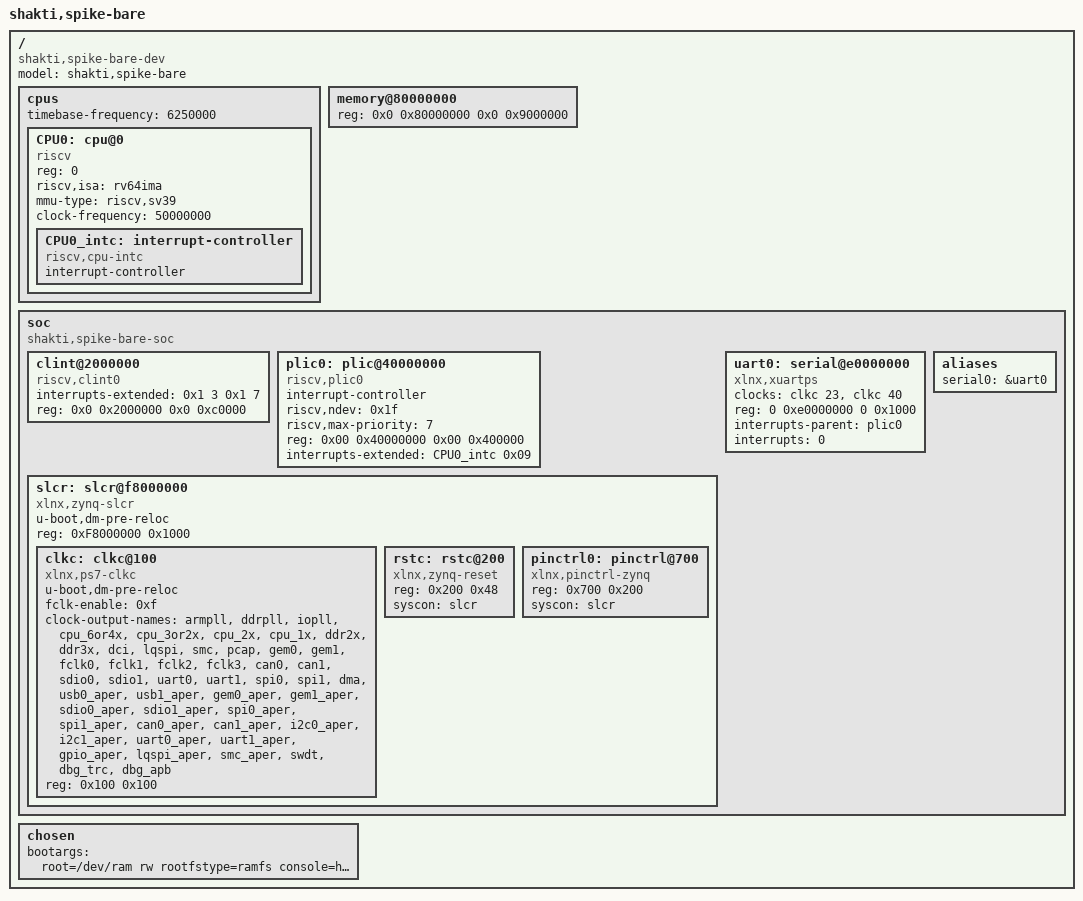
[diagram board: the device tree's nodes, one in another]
/dts-v1/;

/ {
  #address-cells = <2>;
  #size-cells = <2>;
  compatible = "shakti,spike-bare-dev";
  model = "shakti,spike-bare";

  cpus {
    #address-cells = <1>;
    #size-cells = <0>;
    timebase-frequency = <6250000>;
    
    CPU0: cpu@0 {
      device_type = "cpu";
      reg = <0>;
      status = "okay";
      compatible = "riscv";
      riscv,isa = "rv64ima";
      mmu-type = "riscv,sv39";
      clock-frequency = <50000000>;
      CPU0_intc: interrupt-controller {
        #interrupt-cells = <1>;
        interrupt-controller;
        compatible = "riscv,cpu-intc";
      };
    };
  };
  memory@80000000 {
    device_type = "memory";
    reg = <0x0 0x80000000 0x0 0x9000000 >;
  };
  soc {
    #address-cells = <2>;
    #size-cells = <2>;
    compatible = "shakti,spike-bare-soc", "simple-bus";
    ranges;
    clint@2000000 {
      compatible = "riscv,clint0";
      interrupts-extended = <0x1 3 0x1 7 >;
      reg = <0x0 0x2000000 0x0 0xc0000>;
    };

    plic0: plic@40000000 {
      #interrupt-cells = <1>;
      interrupt-controller;
      compatible = "riscv,plic0";
      riscv,ndev = <0x1f>;
      riscv,max-priority = <7>;
      reg-names = "control";
      reg = <0x00 0x40000000 0x00 0x400000>;
      interrupts-extended = <&CPU0_intc 0x09>;
    };
    slcr: slcr@f8000000 {
			u-boot,dm-pre-reloc;
			#address-cells = <1>;
			#size-cells = <1>;
			compatible = "xlnx,zynq-slcr", "syscon", "simple-mfd";
			reg = <0xF8000000 0x1000>;
			ranges;
			clkc: clkc@100 {
				u-boot,dm-pre-reloc;
				#clock-cells = <1>;
				compatible = "xlnx,ps7-clkc";
				fclk-enable = <0xf>;
				clock-output-names = "armpll", "ddrpll", "iopll", "cpu_6or4x",
						"cpu_3or2x", "cpu_2x", "cpu_1x", "ddr2x", "ddr3x",
						"dci", "lqspi", "smc", "pcap", "gem0", "gem1",
						"fclk0", "fclk1", "fclk2", "fclk3", "can0", "can1",
						"sdio0", "sdio1", "uart0", "uart1", "spi0", "spi1",
						"dma", "usb0_aper", "usb1_aper", "gem0_aper",
						"gem1_aper", "sdio0_aper", "sdio1_aper",
						"spi0_aper", "spi1_aper", "can0_aper", "can1_aper",
						"i2c0_aper", "i2c1_aper", "uart0_aper", "uart1_aper",
						"gpio_aper", "lqspi_aper", "smc_aper", "swdt",
						"dbg_trc", "dbg_apb";
				reg = <0x100 0x100>;
			};

			rstc: rstc@200 {
				compatible = "xlnx,zynq-reset";
				reg = <0x200 0x48>;
				#reset-cells = <1>;
				syscon = <&slcr>;
			};

			pinctrl0: pinctrl@700 {
				compatible = "xlnx,pinctrl-zynq";
				reg = <0x700 0x200>;
				syscon = <&slcr>;
			};
		};

    uart0: serial@e0000000 {
			compatible = "xlnx,xuartps", "cdns,uart-r1p8";
			status = "okay";
			clocks = <&clkc 23>, <&clkc 40>;
			clock-names = "uart_clk", "pclk";
			reg = <0 0xe0000000 0 0x1000>;
            interrupts-parent= <&plic0>;
			interrupts = <0>;
		};
    aliases{
        serial0 = &uart0;
    };
  };

  chosen {
    bootargs = "root=/dev/ram rw rootfstype=ramfs console=hvc0";
  };


};

